# ATtiny40 device description
Architecture: AVR8L; Family: tinyAVR
Registers are 8-bit, access not given, no defined reset value unless marked. A register's access mark holds for its fields unless they carry their own. Offsets are from the block's base; [hi:lo] are bit positions; {n}, {i} and the like mark numbered series.

## CPU — CPU Registers
Instances: CPU 0x00
Parameters: CORE_VERSION=AVR8L_0
0x1F RAMDR — RAM Data Register
0x20 RAMAR — RAM Address Register
0x32 NVMCSR — Non-Volatile Memory Control and Status Register
  [7] NVMBSY — Non-Volatile Memory Busy
0x33 NVMCMD bits used 5:0 — Non-Volatile Memory Command
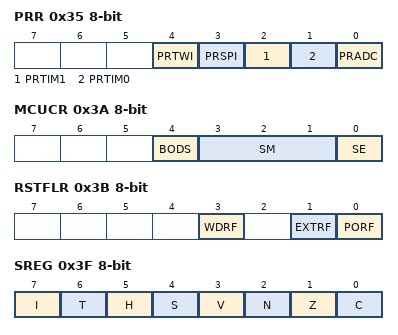
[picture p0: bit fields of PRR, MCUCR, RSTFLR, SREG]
0x35 PRR — Power Reduction Register
  [4] PRTWI — Power Reduction TWI
  [3] PRSPI — Power Reduction Serial Peripheral Interface
  [2] PRTIM1 — Power Reduction Timer/Counter1
  [1] PRTIM0 — Power Reduction Timer/Counter0
  [0] PRADC — Power Reduction ADC
0x36 CLKPSR — Clock Prescale Register
  [3:0] CLKPS — Clock Prescaler Select Bits
    0=1; 1=2; 2=4; 3=8; 4=16; 5=32; 6=64; 7=128; 8=256
0x37 CLKMSR — Clock Main Settings Register
  [1:0] CLKMS — Clock Main Select Bits
0x39 OSCCAL — Oscillator Calibration Value
  [7:0] OSCCAL — Oscillator Calibration
0x3A MCUCR — MCU Control Register
  [4] BODS — BOD Sleep
  [3:1] SM — Sleep Mode
    0=IDLE; 1=ADC (ADC noise reduction); 2=PDOWN (Power-down); 4=STDBY (Standby)
  [0] SE — Sleep Enable
0x3B RSTFLR — Reset Flag Register
  [3] WDRF — Watchdog Reset Flag
  [1] EXTRF — External Reset Flag
  [0] PORF — Power-on Reset Flag
0x3C CCP — Configuration Change Protection
0x3D SP 16-bit — Stack Pointer
0x3F SREG — Status Register
  [7] I — Global Interrupt Enable
  [6] T — Bit Copy Storage
  [5] H — Half Carry Flag
  [4] S — Sign Bit
  [3] V — Two's Complement Overflow Flag
  [2] N — Negative Flag
  [1] Z — Zero Flag
  [0] C — Carry Flag
Value list OSCCAL_VALUE_ADDRESSES: 0=8_0_MHz

## EXINT — External Interrupts
Instances: EXINT 0x00
0x09 PCMSK0 — Pin Change Mask Register 0
  [7:0] PCINT — Pin Change Enable Mask 3
0x0A PCMSK1 — Pin Change Mask Register 1
  [3:0] PCINT (bit 8 of the value upward) — Pin Change Enable Mask 3
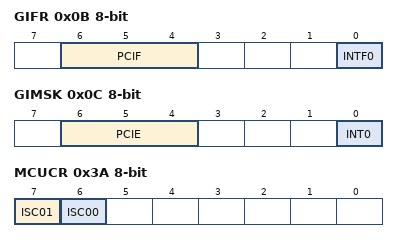
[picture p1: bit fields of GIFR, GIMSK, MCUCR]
0x0B GIFR — General Interrupt Flag Register
  [6:4] PCIF — Pin Change Interrupt Flags
  [0] INTF0 — External Interrupt Flag 0
0x0C GIMSK — General Interrupt Mask Register
  [6:4] PCIE — Pin Change Interrupt Enables
  [0] INT0 — External Interrupt Request 0 Enable
0x1A PCMSK2 — Pin Change Mask Register 2
  [5:0] PCINT (bit 12 of the value upward) — Pin Change Enable Mask 3
0x3A MCUCR — MCU Control Register
  [7] ISC01 — Interrupt Sense Control 0 Bit 1
  [6] ISC00 — Interrupt Sense Control 0 Bit 0
    0=Low Level of INTX; 1=Any logical change on INTX; 2=Falling Edge of INTX; 3=Rising Edge of INTX

## PORTB — I/O Port
Instances: PORTB 0x00
0x04 PINB bits used 3:0 — Port B Data register
0x05 DDRB bits used 3:0 — Data Direction Register, Port B
0x06 PORTB bits used 3:0 — Input Pins, Port B
0x07 PUEB bits used 3:0 — Pull-up Enable Control Register
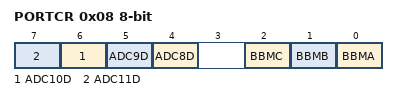
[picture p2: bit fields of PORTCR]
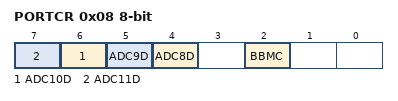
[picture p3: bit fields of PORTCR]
0x08 PORTCR — Port Control Register
  [n-4] ADC{n}D (n=8..11)
  [2] BBMC — Break-Before-Make Mode Enable
  [1] BBMB — Break-Before-Make Mode Enable
  [0] BBMA — Break-Before-Make Mode Enable

## PORTC — I/O Port
Instances: PORTC 0x00
0x08 PORTCR — Port Control Register
  [n-4] ADC{n}D (n=8..11)
  [2] BBMC — Break-Before-Make Mode Enable
0x1B PINC bits used 5:0 — Port C Input Pins
0x1C DDRC bits used 5:0 — Data Direction Register, Port C
0x1D PORTC bits used 5:0 — Port C Data Register
0x1E PUEC bits used 5:0 — Pull-up Enable Control Register

## PORTA — I/O Port
Instances: PORTA 0x00
0x00 PINA — Port A Input Pins
0x01 DDRA — Data Direction Register, Port A
0x02 PORTA — Port A Data Register
0x03 PUEA — Pull-up Enable Control Register
0x08 PORTCR — Port Control Register
  [0] BBMA — Break-Before-Make Mode Enable

## TC0 (TC8 module) — Timer/Counter, 8-bit
Instances: TC0 0x00
0x15 OCR0B — Timer/Counter0 Output Compare Register
0x16 OCR0A — Timer/Counter0 Output Compare Register
0x17 TCNT0 — Timer/Counter0
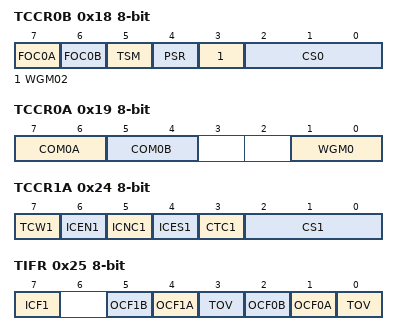
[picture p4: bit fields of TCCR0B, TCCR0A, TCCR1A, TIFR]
0x18 TCCR0B — Timer/Counter 0 Control Register B
  [7] FOC0A — Force Output Compare A
  [6] FOC0B — Force Output Compare B
  [5] TSM — Timer/Counter Synchronization Mode
  [4] PSR — Prescaler Reset Timer/Counter
  [3] WGM02 — Waveform Generation Mode
  [2:0] CS0 — Clock Select
    0=No Clock Source (Stopped); 1=Running, No Prescaling; 2=Running, CLK/8; 3=Running, CLK/64; 4=Running, CLK/256; 5=Running, CLK/1024; 6=Running, ExtClk Tx Falling Edge; 7=Running, ExtClk Tx Rising Edge
0x19 TCCR0A — Timer/Counter 0 Control Register A
  [7:6] COM0A — Compare Output Mode for Channel A bits
  [5:4] COM0B — Compare Output Mode for Channel B bits
  [1:0] WGM0 — Waveform Generation Mode
0x21 OCR1B — Timer/Counter 1 Output Compare Register B
0x22 OCR1A — Timer/Counter 1 Output Compare Register A
0x23 TCNT1L — Timer/Counter1 Low
0x24 TCCR1A — Timer/Counter1 Control Register A
  [7] TCW1 — Timer/Counter1 Width
  [6] ICEN1 — Input Capture Mode Enable
  [5] ICNC1 — : Input Capture Noise Canceler
  [4] ICES1 — Input Capture Edge Select
  [3] CTC1 — Waveform Generation Mode
  [2:0] CS1 — The Clock Select1 bits 2, 1, and 0 define the prescaling source of Timer1.
0x25 TIFR — Overflow Interrupt Enable
  [7] ICF1 — Input Capture Flag
  [5] OCF1B — Timer Output Compare Flag 1B
  [4] OCF1A — Timer Output Compare Flag 1A
  [2] OCF0B — Output Compare Flag 0 B
  [1] OCF0A — Output Compare Flag 0 A
  [3,0] TOV — Timer Overflow Flag
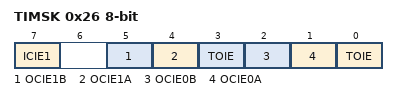
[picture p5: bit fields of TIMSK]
0x26 TIMSK — Timer Interrupt Mask Register
  [7] ICIE1 — Input Capture Interrupt Enable
  [5] OCIE1B — Output Compare B Match Interrupt Enable
  [4] OCIE1A — Output Compare A Match Interrupt Enable
  [2] OCIE0B — Timer/Counter Output Compare Match B Interrupt Enable
  [1] OCIE0A — Timer/Counter0 Output Compare Match A Interrupt Enable
  [3,0] TOIE — Overflow Interrupt Enable
0x27 TCNT1H — Timer/Counter1 High

## SPI — Serial Peripheral Interface
Instances: SPI 0x00
0x2E SPDR — SPI Data Register
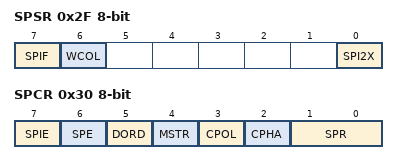
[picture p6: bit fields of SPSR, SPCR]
0x2F SPSR — SPI Status Register
  [7] SPIF — SPI Interrupt Flag
  [6] WCOL — Write Collision Flag
  [0] SPI2X — Double SPI Speed Bit
0x30 SPCR — SPI Control Register
  [7] SPIE — SPI Interrupt Enable
  [6] SPE — SPI Enable
  [5] DORD — Data Order
  [4] MSTR — Master/Slave Select
  [3] CPOL — Clock polarity
  [2] CPHA — Clock Phase
  [1:0] SPR — SPI Clock Rate Selects
    0=fcl/4; 1=fcl/16; 2=fcl/64; 3=fcl/128
